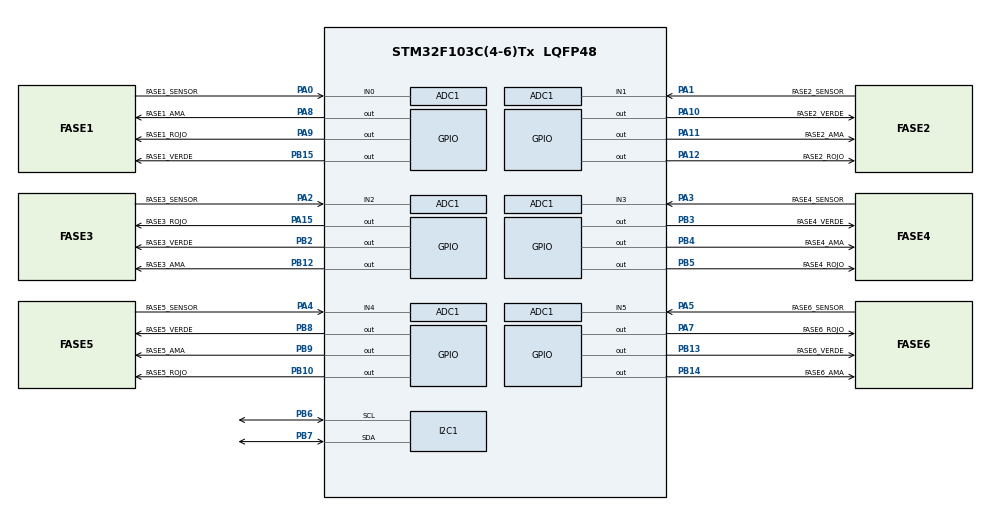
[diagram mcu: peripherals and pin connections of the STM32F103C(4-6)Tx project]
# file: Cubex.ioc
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ADC1.Channel-0\#ChannelRegularConversion=ADC_CHANNEL_1
ADC1.NbrOfConversionFlag=1
ADC1.Rank-0\#ChannelRegularConversion=1
ADC1.SamplingTime-0\#ChannelRegularConversion=ADC_SAMPLETIME_1CYCLE_5
ADC1.master=1
Mcu.Family=STM32F1
Mcu.Name=STM32F103C(4-6)Tx
Mcu.Package=LQFP48
NVIC.ADC1_2_IRQn=true\:0\:0\:false\:true\:true\:2\:true\:true
NVIC.I2C1_ER_IRQn=true\:0\:0\:false\:false\:true\:true\:true
NVIC.I2C1_EV_IRQn=true\:0\:0\:false\:false\:true\:true\:true
NVIC.PriorityGroup=NVIC_PRIORITYGROUP_4
NVIC.RCC_IRQn=true\:0\:0\:false\:true\:true\:1\:true\:false
PA0-WKUP.GPIO_Label=FASE1_SENSOR
PA0-WKUP.Signal=ADCx_IN0
PA1.GPIO_Label=FASE2_SENSOR
PA1.GPIO_Mode=GPIO_MODE_ANALOG
PA1.Signal=SharedAnalog_PA1
PA10.GPIO_Label=FASE2_VERDE
PA10.GPIO_ModeDefaultOutputPP=GPIO_MODE_OUTPUT_PP
PA10.GPIO_PuPd=GPIO_NOPULL
PA10.GPIO_Speed=GPIO_SPEED_FREQ_LOW
PA10.PinState=GPIO_PIN_RESET
PA10.Signal=GPIO_Output
PA11.GPIO_Label=FASE2_AMA
PA11.GPIO_ModeDefaultOutputPP=GPIO_MODE_OUTPUT_PP
PA11.GPIO_PuPd=GPIO_NOPULL
PA11.GPIO_Speed=GPIO_SPEED_FREQ_LOW
PA11.PinState=GPIO_PIN_RESET
PA11.Signal=GPIO_Output
PA12.GPIO_Label=FASE2_ROJO
PA12.GPIO_ModeDefaultOutputPP=GPIO_MODE_OUTPUT_PP
PA12.GPIO_PuPd=GPIO_NOPULL
PA12.GPIO_Speed=GPIO_SPEED_FREQ_LOW
PA12.PinState=GPIO_PIN_RESET
PA12.Signal=GPIO_Output
PA13.Mode=Serial_Wire
PA13.Signal=SYS_JTMS-SWDIO
PA14.Mode=Serial_Wire
PA14.Signal=SYS_JTCK-SWCLK
PA15.GPIO_Label=FASE3_ROJO
PA15.GPIO_ModeDefaultOutputPP=GPIO_MODE_OUTPUT_PP
PA15.GPIO_PuPd=GPIO_NOPULL
PA15.GPIO_Speed=GPIO_SPEED_FREQ_LOW
PA15.PinState=GPIO_PIN_RESET
PA15.Signal=GPIO_Output
PA2.GPIO_Label=FASE3_SENSOR
PA2.GPIO_Mode=GPIO_MODE_ANALOG
PA2.Signal=SharedAnalog_PA2
PA3.GPIO_Label=FASE4_SENSOR
PA3.GPIO_Mode=GPIO_MODE_ANALOG
PA3.Signal=SharedAnalog_PA3
PA4.GPIO_Label=FASE5_SENSOR
PA4.GPIO_Mode=GPIO_MODE_ANALOG
PA4.Signal=SharedAnalog_PA4
PA5.GPIO_Label=FASE6_SENSOR
PA5.GPIO_Mode=GPIO_MODE_ANALOG
PA5.Signal=SharedAnalog_PA5
PA7.GPIO_Label=FASE6_ROJO
PA7.GPIO_ModeDefaultOutputPP=GPIO_MODE_OUTPUT_PP
PA7.GPIO_PuPd=GPIO_NOPULL
PA7.GPIO_Speed=GPIO_SPEED_FREQ_LOW
PA7.PinState=GPIO_PIN_RESET
PA7.Signal=GPIO_Output
PA8.GPIO_Label=FASE1_AMA
PA8.GPIO_ModeDefaultOutputPP=GPIO_MODE_OUTPUT_PP
PA8.GPIO_PuPd=GPIO_NOPULL
PA8.GPIO_Speed=GPIO_SPEED_FREQ_LOW
PA8.PinState=GPIO_PIN_RESET
PA8.Signal=GPIO_Output
PA9.GPIO_Label=FASE1_ROJO
PA9.GPIO_ModeDefaultOutputPP=GPIO_MODE_OUTPUT_PP
PA9.GPIO_PuPd=GPIO_NOPULL
PA9.GPIO_Speed=GPIO_SPEED_FREQ_LOW
PA9.PinState=GPIO_PIN_RESET
PA9.Signal=GPIO_Output
PB10.GPIO_Label=FASE5_ROJO
PB10.GPIO_ModeDefaultOutputPP=GPIO_MODE_OUTPUT_PP
PB10.GPIO_PuPd=GPIO_NOPULL
PB10.GPIO_Speed=GPIO_SPEED_FREQ_LOW
PB10.PinState=GPIO_PIN_RESET
PB10.Signal=GPIO_Output
PB12.GPIO_Label=FASE3_AMA
PB12.GPIO_ModeDefaultOutputPP=GPIO_MODE_OUTPUT_PP
PB12.GPIO_PuPd=GPIO_NOPULL
PB12.GPIO_Speed=GPIO_SPEED_FREQ_LOW
PB12.PinState=GPIO_PIN_RESET
PB12.Signal=GPIO_Output
PB13.GPIO_Label=FASE6_VERDE
PB13.GPIO_ModeDefaultOutputPP=GPIO_MODE_OUTPUT_PP
PB13.GPIO_PuPd=GPIO_NOPULL
PB13.GPIO_Speed=GPIO_SPEED_FREQ_LOW
PB13.PinState=GPIO_PIN_RESET
PB13.Signal=GPIO_Output
PB14.GPIO_Label=FASE6_AMA
PB14.GPIO_ModeDefaultOutputPP=GPIO_MODE_OUTPUT_PP
PB14.GPIO_PuPd=GPIO_NOPULL
PB14.GPIO_Speed=GPIO_SPEED_FREQ_LOW
PB14.PinState=GPIO_PIN_RESET
PB14.Signal=GPIO_Output
PB15.GPIO_Label=FASE1_VERDE
PB15.GPIO_ModeDefaultOutputPP=GPIO_MODE_OUTPUT_PP
PB15.GPIO_PuPd=GPIO_NOPULL
PB15.GPIO_Speed=GPIO_SPEED_FREQ_LOW
PB15.PinState=GPIO_PIN_RESET
PB15.Signal=GPIO_Output
PB2.GPIO_Label=FASE3_VERDE
PB2.GPIO_ModeDefaultOutputPP=GPIO_MODE_OUTPUT_PP
PB2.GPIO_PuPd=GPIO_NOPULL
PB2.GPIO_Speed=GPIO_SPEED_FREQ_LOW
PB2.PinState=GPIO_PIN_RESET
PB2.Signal=GPIO_Output
PB3.GPIO_Label=FASE4_VERDE
PB3.GPIO_ModeDefaultOutputPP=GPIO_MODE_OUTPUT_PP
PB3.GPIO_PuPd=GPIO_NOPULL
PB3.GPIO_Speed=GPIO_SPEED_FREQ_LOW
PB3.PinState=GPIO_PIN_RESET
PB3.Signal=GPIO_Output
PB4.GPIO_Label=FASE4_AMA
PB4.GPIO_ModeDefaultOutputPP=GPIO_MODE_OUTPUT_PP
PB4.GPIO_PuPd=GPIO_NOPULL
PB4.GPIO_Speed=GPIO_SPEED_FREQ_LOW
PB4.PinState=GPIO_PIN_RESET
PB4.Signal=GPIO_Output
PB5.GPIO_Label=FASE4_ROJO
PB5.GPIO_ModeDefaultOutputPP=GPIO_MODE_OUTPUT_PP
PB5.GPIO_PuPd=GPIO_NOPULL
PB5.GPIO_Speed=GPIO_SPEED_FREQ_LOW
PB5.PinState=GPIO_PIN_RESET
PB5.Signal=GPIO_Output
PB6.Mode=I2C
PB6.Signal=I2C1_SCL
PB7.Mode=I2C
PB7.Signal=I2C1_SDA
PB8.GPIO_Label=FASE5_VERDE
PB8.GPIO_ModeDefaultOutputPP=GPIO_MODE_OUTPUT_PP
PB8.GPIO_PuPd=GPIO_NOPULL
PB8.GPIO_Speed=GPIO_SPEED_FREQ_LOW
PB8.PinState=GPIO_PIN_RESET
PB8.Signal=GPIO_Output
PB9.GPIO_Label=FASE5_AMA
PB9.GPIO_ModeDefaultOutputPP=GPIO_MODE_OUTPUT_PP
PB9.GPIO_PuPd=GPIO_NOPULL
PB9.GPIO_Speed=GPIO_SPEED_FREQ_LOW
PB9.PinState=GPIO_PIN_RESET
PB9.Signal=GPIO_Output
PC14-OSC32_IN.Mode=LSE-External-Oscillator
PC14-OSC32_IN.Signal=RCC_OSC32_IN
PC15-OSC32_OUT.Mode=LSE-External-Oscillator
PC15-OSC32_OUT.Signal=RCC_OSC32_OUT
ProjectManager.HeapSize=0x200
ProjectManager.StackSize=0x400
ProjectManager.TargetToolchain=STM32CubeIDE
RCC.APB1Freq_Value=8000000
RCC.APB2Freq_Value=8000000
RCC.RTCClockSelection=RCC_RTCCLKSOURCE_LSE
SH.ADCx_IN0.0=ADC1_IN0,IN0
SH.SharedAnalog_PA1.0=GPIO_Analog
SH.SharedAnalog_PA1.1=ADC1_IN1,IN1
SH.SharedAnalog_PA2.0=GPIO_Analog
SH.SharedAnalog_PA2.1=ADC1_IN2,IN2
SH.SharedAnalog_PA3.0=GPIO_Analog
SH.SharedAnalog_PA3.1=ADC1_IN3,IN3
SH.SharedAnalog_PA4.0=GPIO_Analog
SH.SharedAnalog_PA4.1=ADC1_IN4,IN4
SH.SharedAnalog_PA5.0=GPIO_Analog
SH.SharedAnalog_PA5.1=ADC1_IN5,IN5
VP_CRC_VS_CRC.Mode=CRC_Activate
VP_RTC_VS_RTC_Activate.Mode=RTC_Enabled
VP_RTC_VS_RTC_Calendar.Mode=RTC_Calendar
VP_TIM2_VS_ClockSourceINT.Mode=Internal
board=custom

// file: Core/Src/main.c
/* USER CODE BEGIN Header */
/**
  ******************************************************************************
  * @file           : main.c
  * @brief          : Main program body
  ******************************************************************************
  * @attention
  *
  * <h2><center>&copy; Copyright (c) 2020 STMicroelectronics.
  * All rights reserved.</center></h2>
  *
  * This software component is licensed by ST under BSD 3-Clause license,
  * the "License"; You may not use this file except in compliance with the
  * License. You may obtain a copy of the License at:
  *                        opensource.org/licenses/BSD-3-Clause
  *
  ******************************************************************************
  */
/* USER CODE END Header */

#include "main.h"
#include "adc.h"
#include "crc.h"
#include "i2c.h"
#include "rtc.h"
#include "tim.h"
#include "gpio.h"

/* USER CODE BEGIN PV */
uint8_t mensaje[2];

 uint32_t cError;
/* USER CODE END PV */

void SystemClock_Config(void);
static void MX_NVIC_Init(void);
/* USER CODE BEGIN PFP */
void Di_Estado(void);
/* USER CODE END PFP */

int main(void)
{

  /* MCU Configuration--------------------------------------------------------*/

  /* Reset of all peripherals, Initializes the Flash interface and the Systick. */
  HAL_Init();

  /* Configure the system clock */
  SystemClock_Config();

  /* Initialize all configured peripherals */
  MX_GPIO_Init();
  MX_ADC1_Init();
  MX_I2C1_Init();
  MX_RTC_Init();
  MX_TIM2_Init();
  MX_CRC_Init();

  /* Initialize interrupts */
  MX_NVIC_Init();
  /* USER CODE BEGIN 2 */
  HAL_I2C_MspInit(&hi2c1);

    HAL_GPIO_WritePin(GPIOA, FASE1_AMA_Pin, GPIO_PIN_SET);
      HAL_Delay(33000);
      HAL_GPIO_WritePin(GPIOA, FASE1_AMA_Pin, GPIO_PIN_RESET);

    	if(HAL_I2C_Slave_Receive_IT(&hi2c1, mensaje, 1) != HAL_OK)
    	{
    		Di_Estado();
    		HAL_GPIO_WritePin(GPIOA, FASE6_ROJO_Pin, GPIO_PIN_SET);
    	}

    	//HAL_GPIO_WritePin(GPIOA, FASE1_ROJO_Pin, GPIO_PIN_SET);
    	HAL_Delay(5000);

  /* USER CODE END 2 */

  /* Infinite loop */
  while (1)
  {

  }
}

void Di_Estado(void)
{
   	switch(HAL_I2C_GetError(&hi2c1))
    	{
    		case HAL_I2C_ERROR_NONE:
    		{
    			HAL_GPIO_WritePin(GPIOB,FASE3_VERDE_Pin, GPIO_PIN_SET);
    			HAL_GPIO_WritePin(GPIOB,FASE4_VERDE_Pin | FASE4_AMA_Pin | FASE4_ROJO_Pin, GPIO_PIN_RESET);
    		} break;
    		case HAL_I2C_ERROR_BERR:
    		{
    			HAL_GPIO_WritePin(GPIOB,FASE4_VERDE_Pin, GPIO_PIN_SET);
    			HAL_GPIO_WritePin(GPIOB,FASE3_VERDE_Pin | FASE4_AMA_Pin | FASE4_ROJO_Pin, GPIO_PIN_RESET);
    		} break;
    		case HAL_I2C_ERROR_ARLO:
    		{
    			HAL_GPIO_WritePin(GPIOB,FASE3_VERDE_Pin | FASE4_VERDE_Pin, GPIO_PIN_SET);
    			HAL_GPIO_WritePin(GPIOB,FASE4_AMA_Pin | FASE4_ROJO_Pin, GPIO_PIN_RESET);
    		} break;
    		case HAL_I2C_ERROR_AF:
    		{
    			HAL_GPIO_WritePin(GPIOB,FASE4_AMA_Pin, GPIO_PIN_SET);
    			HAL_GPIO_WritePin(GPIOB,FASE3_VERDE_Pin | FASE4_VERDE_Pin | FASE4_ROJO_Pin, GPIO_PIN_RESET);
    		} break;
    		case HAL_I2C_ERROR_OVR:
    		{
    			HAL_GPIO_WritePin(GPIOB, FASE3_VERDE_Pin | FASE4_AMA_Pin, GPIO_PIN_SET);
    			HAL_GPIO_WritePin(GPIOB,FASE4_VERDE_Pin | FASE4_ROJO_Pin, GPIO_PIN_RESET);
    		} break;
    		case HAL_I2C_ERROR_DMA:
    		{
    			HAL_GPIO_WritePin(GPIOB, FASE4_VERDE_Pin | FASE4_AMA_Pin, GPIO_PIN_SET);
    			HAL_GPIO_WritePin(GPIOB,FASE3_VERDE_Pin | FASE4_ROJO_Pin, GPIO_PIN_RESET);
    		} break;
    		case HAL_I2C_ERROR_TIMEOUT:
    		{
    			HAL_GPIO_WritePin(GPIOB,FASE3_VERDE_Pin | FASE4_VERDE_Pin | FASE4_AMA_Pin, GPIO_PIN_SET);
    			HAL_GPIO_WritePin(GPIOB,FASE4_ROJO_Pin, GPIO_PIN_RESET);
    		} break;
    		case HAL_I2C_ERROR_SIZE:
    		{
    			HAL_GPIO_WritePin(GPIOB,FASE4_ROJO_Pin, GPIO_PIN_SET);
    			HAL_GPIO_WritePin(GPIOB,FASE3_VERDE_Pin | FASE4_VERDE_Pin | FASE4_AMA_Pin, GPIO_PIN_RESET);
    		} break;
    		case HAL_I2C_ERROR_DMA_PARAM:
    		{
    			HAL_GPIO_WritePin(GPIOB,FASE3_VERDE_Pin | FASE4_ROJO_Pin, GPIO_PIN_SET);
    			HAL_GPIO_WritePin(GPIOB,FASE3_VERDE_Pin | FASE4_AMA_Pin, GPIO_PIN_RESET);
    		} break;
    	}

    	switch(HAL_I2C_GetState(&hi2c1))	/* Para ver el estado del periférico I2C */
      {								/* en cuando sale de las condiciones.    */
      	  case HAL_I2C_STATE_RESET:
      	  {
      		  HAL_GPIO_WritePin(GPIOB,FASE3_AMA_Pin,GPIO_PIN_SET);
      		  HAL_GPIO_WritePin(GPIOB,FASE6_VERDE_Pin | FASE6_AMA_Pin | FASE1_VERDE_Pin, GPIO_PIN_RESET);
      	  } break;
      	  case HAL_I2C_STATE_READY:
      	  {
      		  HAL_GPIO_WritePin(GPIOB,FASE6_VERDE_Pin,GPIO_PIN_SET);
      		  HAL_GPIO_WritePin(GPIOB,FASE3_AMA_Pin | FASE6_AMA_Pin | FASE1_VERDE_Pin, GPIO_PIN_RESET);
      	  } break;
      	  case HAL_I2C_STATE_BUSY:
      	  {
      		  HAL_GPIO_WritePin(GPIOB,FASE3_AMA_Pin | FASE6_VERDE_Pin,GPIO_PIN_SET);
      		  HAL_GPIO_WritePin(GPIOB,FASE6_AMA_Pin | FASE1_VERDE_Pin, GPIO_PIN_RESET);
      	  } break;
      	  case HAL_I2C_STATE_BUSY_TX:
      	  {
      		  HAL_GPIO_WritePin(GPIOB,FASE6_AMA_Pin,GPIO_PIN_SET);
      		  HAL_GPIO_WritePin(GPIOB,FASE3_AMA_Pin | FASE6_VERDE_Pin | FASE1_VERDE_Pin, GPIO_PIN_RESET);
      	  } break;
      	  case HAL_I2C_STATE_BUSY_RX:
      	  {
      		  HAL_GPIO_WritePin(GPIOB,FASE3_AMA_Pin | FASE6_AMA_Pin,GPIO_PIN_SET);
      		  HAL_GPIO_WritePin(GPIOB,FASE6_VERDE_Pin | FASE1_VERDE_Pin, GPIO_PIN_RESET);
      	  } break;
      	  case HAL_I2C_STATE_LISTEN:
      	  {
      		  HAL_GPIO_WritePin(GPIOB,FASE6_VERDE_Pin | FASE6_AMA_Pin,GPIO_PIN_SET);
      		  HAL_GPIO_WritePin(GPIOB,FASE3_AMA_Pin | FASE1_VERDE_Pin, GPIO_PIN_RESET);
      	  } break;
      	  case HAL_I2C_STATE_BUSY_TX_LISTEN:
      	  {
      		  HAL_GPIO_WritePin(GPIOB,FASE3_AMA_Pin | FASE6_VERDE_Pin | FASE6_AMA_Pin,GPIO_PIN_SET);
      		  HAL_GPIO_WritePin(GPIOB,FASE1_VERDE_Pin, GPIO_PIN_RESET);
      	  } break;
      	  case HAL_I2C_STATE_BUSY_RX_LISTEN:
      	  {
      		  HAL_GPIO_WritePin(GPIOB,FASE1_VERDE_Pin,GPIO_PIN_SET);
      		  HAL_GPIO_WritePin(GPIOB,FASE3_AMA_Pin | FASE6_VERDE_Pin | FASE6_AMA_Pin, GPIO_PIN_RESET);
      	  } break;
      	  case HAL_I2C_STATE_ABORT:
      	  {
      		  HAL_GPIO_WritePin(GPIOB,FASE3_AMA_Pin | FASE1_VERDE_Pin,GPIO_PIN_SET);
      		  HAL_GPIO_WritePin(GPIOB,FASE6_VERDE_Pin | FASE6_AMA_Pin, GPIO_PIN_RESET);
      	  } break;
      	  case HAL_I2C_STATE_TIMEOUT:
      	  {
      		  HAL_GPIO_WritePin(GPIOB,FASE3_AMA_Pin | FASE6_VERDE_Pin,GPIO_PIN_SET);
      		  HAL_GPIO_WritePin(GPIOB,FASE6_AMA_Pin | FASE1_AMA_Pin, GPIO_PIN_RESET);
      	  } break;
      	  case HAL_I2C_STATE_ERROR:
      	  {
      		  HAL_GPIO_WritePin(GPIOB,FASE3_AMA_Pin | FASE6_VERDE_Pin | FASE6_AMA_Pin,GPIO_PIN_SET);
      		  HAL_GPIO_WritePin(GPIOB,FASE1_VERDE_Pin, GPIO_PIN_RESET);
      	  } break;
      }
}
void SystemClock_Config(void)
{
  RCC_OscInitTypeDef RCC_OscInitStruct = {0};
  RCC_ClkInitTypeDef RCC_ClkInitStruct = {0};
  RCC_PeriphCLKInitTypeDef PeriphClkInit = {0};

  /** Initializes the CPU, AHB and APB busses clocks
  */
  RCC_OscInitStruct.OscillatorType = RCC_OSCILLATORTYPE_HSI|RCC_OSCILLATORTYPE_LSE;
  RCC_OscInitStruct.LSEState = RCC_LSE_ON;
  RCC_OscInitStruct.HSIState = RCC_HSI_ON;
  RCC_OscInitStruct.HSICalibrationValue = RCC_HSICALIBRATION_DEFAULT;
  RCC_OscInitStruct.PLL.PLLState = RCC_PLL_NONE;
  if (HAL_RCC_OscConfig(&RCC_OscInitStruct) != HAL_OK)
  {
    Error_Handler();
  }
  /** Initializes the CPU, AHB and APB busses clocks
  */
  RCC_ClkInitStruct.ClockType = RCC_CLOCKTYPE_HCLK|RCC_CLOCKTYPE_SYSCLK
                              |RCC_CLOCKTYPE_PCLK1|RCC_CLOCKTYPE_PCLK2;
  RCC_ClkInitStruct.SYSCLKSource = RCC_SYSCLKSOURCE_HSI;
  RCC_ClkInitStruct.AHBCLKDivider = RCC_SYSCLK_DIV1;
  RCC_ClkInitStruct.APB1CLKDivider = RCC_HCLK_DIV1;
  RCC_ClkInitStruct.APB2CLKDivider = RCC_HCLK_DIV1;

  if (HAL_RCC_ClockConfig(&RCC_ClkInitStruct, FLASH_LATENCY_0) != HAL_OK)
  {
    Error_Handler();
  }
  PeriphClkInit.PeriphClockSelection = RCC_PERIPHCLK_RTC|RCC_PERIPHCLK_ADC;
  PeriphClkInit.RTCClockSelection = RCC_RTCCLKSOURCE_LSE;
  PeriphClkInit.AdcClockSelection = RCC_ADCPCLK2_DIV2;
  if (HAL_RCCEx_PeriphCLKConfig(&PeriphClkInit) != HAL_OK)
  {
    Error_Handler();
  }
}

/**
  * @brief NVIC Configuration.
  * @retval None
  */
static void MX_NVIC_Init(void)
{
  /* RCC_IRQn interrupt configuration */
  HAL_NVIC_SetPriority(RCC_IRQn, 0, 0);
  HAL_NVIC_EnableIRQ(RCC_IRQn);
  /* ADC1_2_IRQn interrupt configuration */
  HAL_NVIC_SetPriority(ADC1_2_IRQn, 0, 0);
  HAL_NVIC_EnableIRQ(ADC1_2_IRQn);
}

void Error_Handler(void)
{
}

/************************ (C) COPYRIGHT STMicroelectronics *****END OF FILE****/
